# RN821X_RN721X_SOC_V2 register map
File version: v1.0.7
CPU: CM0 r0p0, little endian, no MPU, no FPU, 3 interrupt priority bits
Registers are 32-bit, read-write, reset 0x0 unless marked. A register's access mark holds for its fields unless they carry their own. Offsets are from the block's base; [hi:lo] are bit positions; 'fields as' and 'values as' point back to an identical list.

## NVM — no voltage module
Base 0x40040000
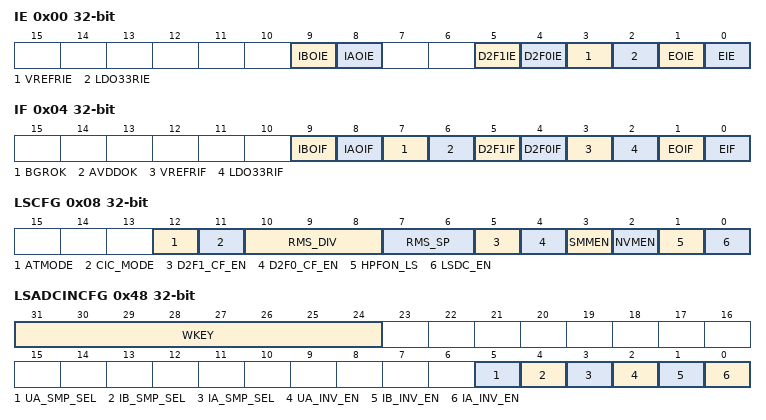
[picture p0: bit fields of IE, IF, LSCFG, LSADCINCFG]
0x00 IE — interrupt enables
  [9] IBOIE — ib d2f is done and overflow
    0=DIS (do not generate interrupt when d2f1 pulse is output); 1=EN (generate interrupt when d2f1 pulse is output)
  [8] IAOIE — ia d2f is done and overflow
    values as IBOIE
  [5] D2F1IE — d2f1 pulse interrupt enable
    values as IBOIE
  [4] D2F0IE — d2f0 pulse interrupt enable
    0=DIS (do not generate interrupt when d2f0 pulse is output); 1=EN (generate interrupt when d2f0 pulse is output)
  [3] VREFRIE — VREF reset interrupt enable
    0=DIS (do not generate interrupt when VREF reset found); 1=EN (generate interrupt when VREF reset found)
  [2] LDO33RIE — LDO33 reset interrupt enable
    0=DIS (do not generate interrupt when reset found in LDO33 power domain); 1=EN (generate interrupt when reset found in LDO33 power domain)
  [1] EOIE — NV end and overflow interrupt enable
    0=DIS (do not generate interrupt when NV computation ends and NV value beyond threshold); 1=EN (generate interrupt when NV computation ends and NV value beyond threshold)
  [0] EIE — NV end interrupt enable
    0=DIS (do not generate interrupt when NV computation ends); 1=EN (generate interrupt when NV computation ends)
0x04 IF — interrupt flag
  [9] IBOIF — ib d2f end and overflow flag
    0=NULL (no pending event of d2f1 impulse); 1=OCC (pending event of d2f1 impulse interrupt flag)
  [8] IAOIF — ia d2f end and overflow flag
    values as IBOIF
  [7] BGROK — bgr power ok
    0=NULL (power not ok); 1=OK (power ok)
  [6] AVDDOK — avdd power ok
    0=NULL (power not ok); 1=OK (power ok)
  [5] D2F1IF — d2f1 impulse interrupt flag
    values as IBOIF
  [4] D2F0IF — d2f0 impulse interrupt flag
    0=NULL (no pending event of d2f0 impulse); 1=OCC (pending event of d2f0 impulse interrupt flag)
  [3] VREFRIF — VREF reset interrupt flag
    0=NULL (no pending event of VREF domain reset); 1=OCC (pending event of VREF domain reset found)
  [2] LDO33RIF — LDO33 reset interrupt flag
    0=NULL (no pending event of LDO33 power domain reset); 1=OCC (pending event of LDO33 power domain reset found)
  [1] EOIF — NV end and overflow interrupt flag
    0=NULL (no pending event of NV computation ends and NV value beyond threshold); 1=OCC (pending event of NV computation ends and NV value beyond threshold found)
  [0] EIF — NV end interrupt flag
    values as EOIF
0x08 LSCFG — NV config
  [12] ATMODE — d2f auto mode
    0=WITHPWR (d2f without power); 1=NOPWR (d2f with power)
  [11] CIC_MODE
    0=128POINTS (128 points per wave); 1=AUTO (by frequency compensation)
  [10:8] RMS_DIV — RMSL_IA and RMSL_IB div
    0=P0 (no average); 1=P1 (2 points average); 2=P2 (4 points average); 3=P3 (8 points average); 4=P4 (16 points average); 5=P5 (32 points average); 6=P6 (64 points average); 7=P7 (128 points average)
  [7:6] RMS_SP — RMSL_IA and RMSL_IB output configuration
    0=P0 (rms accumulate at the 1st point); 1=P1 (rms accumulate at the 2nd point); 2=P2 (rms accumulate at the 3rd point); 3=P3 (rms accumulate at the 4th point)
  [5] D2F1_CF_EN — SMM enable
    0=DIS (D2F1 pulse not output to io); 1=EN (D2F1 pulse output to io)
  [4] D2F0_CF_EN — SMM enable
    0=DIS; 1=EN
  [3] SMMEN — SMM enable
    0=DIS (RMS updated every 20ms); 1=EN (RMS updated every 80ms)
  [2] NVMEN — module enable
    0=DIS (disabled); 1=EN (enabled)
  [1] HPFON_LS — high pass filter enable
    0=DIS (disabled); 1=EN (enabled)
  [0] LSDC_EN — automatic DC offset calibration enable
    0=DIS (disabled); 1=EN (enabled)
0x0C LSDCOS — NV measurement DC offset.
  [23:0] LSDCOS
0x10 LSTHO — NV measurement threshold
  [23:0] LSTHO
0x14 LSRMS ro — IA cyclic updated NV measurement RMS
  [23:0] LSRMS
0x18 LSRMS1 ro — IA RMS_L1 will not change after calculation
  [23:0] LSRMS1
0x20 HFCONST — HF const value
  [15:0] HFCONST
0x24 D2FP0 — D2F power 0 vaule
  [23:0] D2FP0
0x28 D2FP1 — D2F power 1 vaule
  [23:0] D2FP1
0x2C LSMODE — NV mode
  [15:0] NVM_MODE — NVM MODE cfg bits
0x30 LSDCOSIB — IB dc offset
  [23:0] LSDCOSIB — IB dc offset bits
0x34 LSTHOIB — IB DC threshold
  [23:0] LSTHOIB — IB DC threshold bits
0x38 LSGSIA — IA rms gain
  [15:0] LSGSIA — IA rms gain bits
0x3C LSGSIB — IB rms gain
  [15:0] LSGSIB — IB rms gain bits
0x40 LSRMSIB — IB cyclic updated NV measurement RMS
  [23:0] LSRMSIB
0x44 LSRMSIB1 — IB RMS_L1 will not change after calculation
  [23:0] LSRMSIB1
0x48 LSADCINCFG — adc input configuration
  [31:24] WKEY wo — register write password
  [5] UA_SMP_SEL — UA sample edge select bit
    0=PE (select as negedge); 1=NE (select as posedge)
  [4] IB_SMP_SEL — IB sample edge select bit
    0=PE (select as negedge); 1=NE (select as posedge)
  [3] IA_SMP_SEL — IA sample edge select bit
    0=PE (select as negedge); 1=NE (select as posedge)
  [2] UA_INV_EN — UA invert enable bit
    0=NUL (not function); 1=REV (reverse)
  [1] IB_INV_EN — IB invert enable bit
    0=NUL (not function); 1=REV (reverse)
  [0] IA_INV_EN — IA invert enable bit
    0=NUL (not function); 1=REV (reverse)
0x4C LSRMSUA — U user define rms
  [23:0] LSRMSUA — U user define rms bits
0x50 LSPA — IA user define power
  [23:0] LSPA — IA user define power bits
0x54 LSPB — IB user define power
  [23:0] LSPB — IB user define power bits
